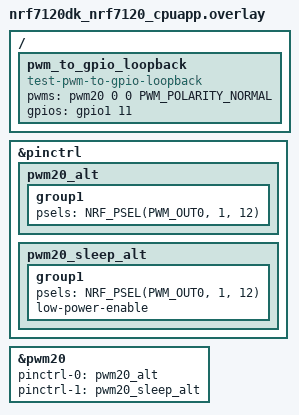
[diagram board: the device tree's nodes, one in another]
/*
 * Copyright (c) 2025 Nordic Semiconductor ASA
 *
 * SPDX-License-Identifier: LicenseRef-Nordic-5-Clause
 */

#include <zephyr/dt-bindings/pwm/pwm.h>
#include <zephyr/dt-bindings/gpio/nordic-nrf-gpio.h>

/*
 * Test requires jumper between:
 *  - PWM20 OUT[0] at P1.12 <-> GPIO input at P1.11
 */

&pinctrl {
	pwm20_alt: pwm20_alt {
		group1 {
			psels = <NRF_PSEL(PWM_OUT0, 1, 12)>;
		};
	};

	pwm20_sleep_alt: pwm20_sleep_alt {
		group1 {
			psels = <NRF_PSEL(PWM_OUT0, 1, 12)>;
			low-power-enable;
		};
	};
};

&pwm20 {
	status = "okay";
	pinctrl-0 = <&pwm20_alt>;
	pinctrl-1 = <&pwm20_sleep_alt>;
	pinctrl-names = "default", "sleep";
};

/ {
	pwm_to_gpio_loopback: pwm_to_gpio_loopback {
		compatible = "test-pwm-to-gpio-loopback";
		pwms = <&pwm20 0 0 PWM_POLARITY_NORMAL>;
		gpios = <&gpio1 11 GPIO_ACTIVE_HIGH>;
	};
};
